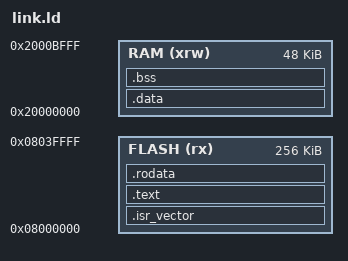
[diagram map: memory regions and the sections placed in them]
MEMORY
{
  FLASH (rx)  : ORIGIN = 0x08000000, LENGTH = 256K
  RAM   (xrw) : ORIGIN = 0x20000000, LENGTH = 48K
}

_estack = ORIGIN(RAM) + LENGTH(RAM);

SECTIONS
{
  .isr_vector : { KEEP(*(.isr_vector)) } > FLASH
  .text : { *(.text*) *(.glue_7*) *(.glue_7t*) } > FLASH
  .rodata : { *(.rodata*) } > FLASH

  _sidata = .;

  .data : AT(_sidata)
  {
    _sdata = .;
    *(.data*)
    _edata = .;
  } > RAM

  .bss :
  {
    _sbss = .;
    *(.bss*)
    *(COMMON)
    _ebss = .;
  } > RAM

  PROVIDE(end = .);
}
